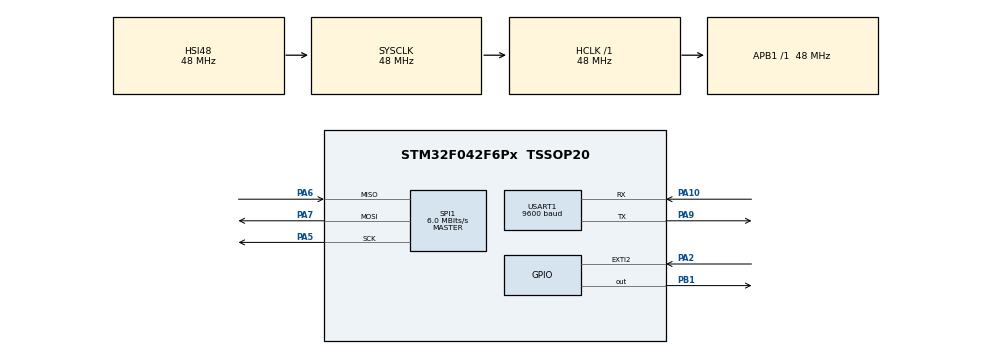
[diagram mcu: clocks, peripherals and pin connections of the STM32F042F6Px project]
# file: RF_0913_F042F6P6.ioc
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Dma.Request0=USART1_RX
Dma.Request1=USART1_TX
Dma.USART1_RX.0.Direction=DMA_PERIPH_TO_MEMORY
Dma.USART1_RX.0.Instance=DMA1_Channel3
Dma.USART1_RX.0.MemDataAlignment=DMA_MDATAALIGN_BYTE
Dma.USART1_RX.0.MemInc=DMA_MINC_ENABLE
Dma.USART1_RX.0.Mode=DMA_CIRCULAR
Dma.USART1_RX.0.PeriphDataAlignment=DMA_PDATAALIGN_BYTE
Dma.USART1_RX.0.PeriphInc=DMA_PINC_DISABLE
Dma.USART1_RX.0.Priority=DMA_PRIORITY_HIGH
Dma.USART1_TX.1.Direction=DMA_MEMORY_TO_PERIPH
Dma.USART1_TX.1.Instance=DMA1_Channel2
Dma.USART1_TX.1.MemDataAlignment=DMA_MDATAALIGN_BYTE
Dma.USART1_TX.1.MemInc=DMA_MINC_ENABLE
Dma.USART1_TX.1.Mode=DMA_NORMAL
Dma.USART1_TX.1.PeriphDataAlignment=DMA_PDATAALIGN_BYTE
Dma.USART1_TX.1.PeriphInc=DMA_PINC_DISABLE
Dma.USART1_TX.1.Priority=DMA_PRIORITY_HIGH
Mcu.Family=STM32F0
Mcu.Name=STM32F042F6Px
Mcu.Package=TSSOP20
NVIC.DMA1_Channel2_3_IRQn=true\:0\:0\:false\:false\:true
NVIC.EXTI2_3_IRQn=true\:0\:0\:false\:false\:true
NVIC.USART1_IRQn=true\:0\:0\:false\:false\:true
PA10.Mode=Asynchronous
PA10.Signal=USART1_RX
PA13.Mode=Serial_Wire
PA13.Signal=SYS_SWDIO
PA14.Mode=Serial_Wire
PA14.Signal=SYS_SWCLK
PA2.GPIO_ModeDefaultEXTI=GPIO_MODE_IT_FALLING
PA2.Signal=GPXTI2
PA5.GPIO_PuPd=GPIO_PULLDOWN
PA5.Mode=Full_Duplex_Master
PA5.Signal=SPI1_SCK
PA6.Mode=Full_Duplex_Master
PA6.Signal=SPI1_MISO
PA7.Mode=Full_Duplex_Master
PA7.Signal=SPI1_MOSI
PA9.Mode=Asynchronous
PA9.Signal=USART1_TX
PB1.PinState=GPIO_PIN_SET
PB1.Signal=GPIO_Output
ProjectManager.HeapSize=0x200
ProjectManager.StackSize=0x400
ProjectManager.TargetToolchain=MDK-ARM V5
RCC.AHBFreq_Value=48000000
RCC.APB1Freq_Value=48000000
RCC.APB1TimFreq_Value=48000000
RCC.HCLKFreq_Value=48000000
RCC.SYSCLKFreq_VALUE=48000000
RCC.SYSCLKSource=RCC_SYSCLKSOURCE_HSI48
SPI1.BaudRatePrescaler=SPI_BAUDRATEPRESCALER_8
SPI1.CalculateBaudRate=6.0 MBits/s
SPI1.DataSize=SPI_DATASIZE_8BIT
SPI1.Mode=SPI_MODE_MASTER
USART1.AutoBaudRateEnableParam=UART_ADVFEATURE_AUTOBAUDRATE_DISABLE
USART1.BaudRate=9600
USART1.WordLength=UART_WORDLENGTH_8B
VP_IWDG_VS_IWDG.Mode=IWDG_Activate
board=RF_0913_F042F6P6

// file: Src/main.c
/**
  ******************************************************************************
  * File Name          : main.c
  * Description        : Main program body
  ******************************************************************************
  *
  * COPYRIGHT(c) 2016 STMicroelectronics
  *
  * Redistribution and use in source and binary forms, with or without modification,
  * are permitted provided that the following conditions are met:
  *   1. Redistributions of source code must retain the above copyright notice,
  *      this list of conditions and the following disclaimer.
  *   2. Redistributions in binary form must reproduce the above copyright notice,
  *      this list of conditions and the following disclaimer in the documentation
  *      and/or other materials provided with the distribution.
  *   3. Neither the name of STMicroelectronics nor the names of its contributors
  *      may be used to endorse or promote products derived from this software
  *      without specific prior written permission.
  *
  * THIS SOFTWARE IS PROVIDED BY THE COPYRIGHT HOLDERS AND CONTRIBUTORS "AS IS"
  * AND ANY EXPRESS OR IMPLIED WARRANTIES, INCLUDING, BUT NOT LIMITED TO, THE
  * IMPLIED WARRANTIES OF MERCHANTABILITY AND FITNESS FOR A PARTICULAR PURPOSE ARE
  * DISCLAIMED. IN NO EVENT SHALL THE COPYRIGHT HOLDER OR CONTRIBUTORS BE LIABLE
  * FOR ANY DIRECT, INDIRECT, INCIDENTAL, SPECIAL, EXEMPLARY, OR CONSEQUENTIAL
  * DAMAGES (INCLUDING, BUT NOT LIMITED TO, PROCUREMENT OF SUBSTITUTE GOODS OR
  * SERVICES; LOSS OF USE, DATA, OR PROFITS; OR BUSINESS INTERRUPTION) HOWEVER
  * CAUSED AND ON ANY THEORY OF LIABILITY, WHETHER IN CONTRACT, STRICT LIABILITY,
  * OR TORT (INCLUDING NEGLIGENCE OR OTHERWISE) ARISING IN ANY WAY OUT OF THE USE
  * OF THIS SOFTWARE, EVEN IF ADVISED OF THE POSSIBILITY OF SUCH DAMAGE.
  *
  ******************************************************************************
  */
#include "stm32f0xx_hal.h"

/* USER CODE BEGIN Includes */
#include "stm32f0xx.h"
#include "main.h"
#include "flash.h"
#include "CC1121.h"
#include "CC1121_gpio.h"
#include "RF_parameter_setting.h"
#include "systick_timer.h"

/* USER CODE END Includes */

IWDG_HandleTypeDef hiwdg;

SPI_HandleTypeDef hspi1;

UART_HandleTypeDef huart1;
DMA_HandleTypeDef hdma_usart1_rx;
DMA_HandleTypeDef hdma_usart1_tx;

/* USER CODE BEGIN PV */
/* Private variables ---------------------------------------------------------*/
extern CC1121_RF_RX_DATA RF_RECEIVE_DATA;;
extern CC1121_RF_txDATA_DEF  Data_Packet_Tx;
#define u8 unsigned char
unsigned char uart_dma_state=1;

uint32_t uBrate=9600;
/* USER CODE END PV */

void SystemClock_Config(void);
void Error_Handler(void);
static void MX_GPIO_Init(void);
static void MX_DMA_Init(void);
static void MX_IWDG_Init(void);
static void MX_SPI1_Init(void);
static void MX_USART1_UART_Init(void);

/* USER CODE BEGIN PFP */
/* Private function prototypes -----------------------------------------------*/

/* USER CODE END PFP */

/* USER CODE BEGIN 0 */

void HW_RE_Configuration()
{
	Si4463_GpioInt();
	//HAL_DMA_Abort_IT(&hdma_usart1_tx);
	//HAL_DMA_Abort_IT(&hdma_usart1_rx);

	RF_parameters_init();
	RF_parameters_read();

	MX_USART1_UART_Init();
//	sdn_reset();// reset RF
	RF_CC1121_Init();  // RF INIT
//	delay_us(200);
//	spi_read_info();
//	delay_us(200);

	HAL_NVIC_EnableIRQ(EXTI2_3_IRQn);
	HAL_NVIC_ClearPendingIRQ(EXTI2_3_IRQn);
	HAL_NVIC_SetPriority(EXTI2_3_IRQn, 1, 0);
	delay_us(200);
	//rx_init();
	__HAL_UART_CLEAR_IDLEFLAG(&huart1);
	//HAL_IWDG_Start(&hiwdg);//start iwdg
}
void HW_init()
{
	Si4463_GpioInt();
	HAL_DMA_Abort_IT(&hdma_usart1_tx);
	HAL_DMA_Abort_IT(&hdma_usart1_rx);

	RF_parameters_init();
	RF_parameters_read();

	MX_USART1_UART_Init();
	HAL_UART_Receive_DMA(&huart1,Data_Packet_Tx.rf_tx_data_buff,buffer_size);
	__HAL_UART_ENABLE_IT(&huart1, UART_IT_IDLE);    //??????
//  Sample_Timer_Init();
//	sdn_reset();// reset RF
	  //PROC_MANUFACTURE_Do();              //灵敏度测试程序，GPIO0为信号输出433M 9.6K 15K

	  RF_CC1121_Init();  // RF INIT

//	delay_us(200);
//	spi_read_info();
//	delay_us(200);

	HAL_NVIC_EnableIRQ(EXTI2_3_IRQn);
	HAL_NVIC_ClearPendingIRQ(EXTI2_3_IRQn);
	HAL_NVIC_SetPriority(EXTI2_3_IRQn, 1, 0);

	delay_us(200);
	RF_RECEIVE_DATA.rf_receive_end_flag=0;
//	rx_init();
	__HAL_UART_CLEAR_IDLEFLAG(&huart1);

	//HAL_IWDG_Start(&hiwdg);//start iwdg
}

/* USER CODE END 0 */

int main(void)
{

	/* MCU Configuration----------------------------------------------------------*/

	/* Reset of all peripherals, Initializes the Flash interface and the Systick. */
	HAL_Init();

	/* Configure the system clock */
	SystemClock_Config();

	/* Initialize all configured peripherals */
	MX_GPIO_Init();
	MX_DMA_Init();
	MX_IWDG_Init();
	MX_SPI1_Init();
// MX_USART1_UART_Init();

	/* USER CODE BEGIN 2 */
//GetLockCode();
//rev_ID_write(Lock_Code1);
//Lock_Code=0;
//Lock_Code=rev_ID_read();
//	if(Lock_Code != Lock_Code1)
	//	return 0; //??0x123456789ABC??????ID
	HW_init();
	//Sample_Timer_Init();
// IO_TEST();
	/* USER CODE END 2 */

	/* Infinite loop */
	while (1)
	{

		/* USER CODE BEGIN 3 */
		//RF_TX_RX_CTRL();
		RF_Process();
		// HAL_IWDG_Refresh(&hiwdg);//watch dog

	}
	/* USER CODE END 3 */

}

/** System Clock Configuration
*/
void SystemClock_Config(void)
{

	RCC_OscInitTypeDef RCC_OscInitStruct;
	RCC_ClkInitTypeDef RCC_ClkInitStruct;
	RCC_PeriphCLKInitTypeDef PeriphClkInit;

	RCC_OscInitStruct.OscillatorType = RCC_OSCILLATORTYPE_HSI48|RCC_OSCILLATORTYPE_LSI;
	RCC_OscInitStruct.HSI48State = RCC_HSI48_ON;
	RCC_OscInitStruct.LSIState = RCC_LSI_ON;
	RCC_OscInitStruct.PLL.PLLState = RCC_PLL_NONE;
	if (HAL_RCC_OscConfig(&RCC_OscInitStruct) != HAL_OK)
	{
		Error_Handler();
	}

	RCC_ClkInitStruct.ClockType = RCC_CLOCKTYPE_HCLK|RCC_CLOCKTYPE_SYSCLK
	                              |RCC_CLOCKTYPE_PCLK1;
	RCC_ClkInitStruct.SYSCLKSource = RCC_SYSCLKSOURCE_HSI48;
	RCC_ClkInitStruct.AHBCLKDivider = RCC_SYSCLK_DIV1;
	RCC_ClkInitStruct.APB1CLKDivider = RCC_HCLK_DIV1;
	if (HAL_RCC_ClockConfig(&RCC_ClkInitStruct, FLASH_LATENCY_1) != HAL_OK)
	{
		Error_Handler();
	}

	PeriphClkInit.PeriphClockSelection = RCC_PERIPHCLK_USART1;
	PeriphClkInit.Usart1ClockSelection = RCC_USART1CLKSOURCE_PCLK1;
	if (HAL_RCCEx_PeriphCLKConfig(&PeriphClkInit) != HAL_OK)
	{
		Error_Handler();
	}

	HAL_SYSTICK_Config(HAL_RCC_GetHCLKFreq()/1000);

	HAL_SYSTICK_CLKSourceConfig(SYSTICK_CLKSOURCE_HCLK);

	/* SysTick_IRQn interrupt configuration */
	HAL_NVIC_SetPriority(SysTick_IRQn, 0, 0);
}

/* IWDG init function */
static void MX_IWDG_Init(void)
{

	hiwdg.Instance = IWDG;
	hiwdg.Init.Prescaler = IWDG_PRESCALER_4;
	hiwdg.Init.Window = 4095;
	hiwdg.Init.Reload = 4095;
	if (HAL_IWDG_Init(&hiwdg) != HAL_OK)
	{
		Error_Handler();
	}

}

/* SPI1 init function */
static void MX_SPI1_Init(void)
{

	hspi1.Instance = SPI1;
	hspi1.Init.Mode = SPI_MODE_MASTER;
	hspi1.Init.Direction = SPI_DIRECTION_2LINES;
	hspi1.Init.DataSize = SPI_DATASIZE_8BIT;
	hspi1.Init.CLKPolarity = SPI_POLARITY_LOW;
	hspi1.Init.CLKPhase = SPI_PHASE_1EDGE;
	hspi1.Init.NSS = SPI_NSS_SOFT;
	hspi1.Init.BaudRatePrescaler = SPI_BAUDRATEPRESCALER_8;
	hspi1.Init.FirstBit = SPI_FIRSTBIT_MSB;
	hspi1.Init.TIMode = SPI_TIMODE_DISABLE;
	hspi1.Init.CRCCalculation = SPI_CRCCALCULATION_DISABLE;
	hspi1.Init.CRCPolynomial = 7;
	hspi1.Init.CRCLength = SPI_CRC_LENGTH_DATASIZE;
	hspi1.Init.NSSPMode = SPI_NSS_PULSE_ENABLE;
	if (HAL_SPI_Init(&hspi1) != HAL_OK)
	{
		Error_Handler();
	}

}

/* USART1 init function */
static void MX_USART1_UART_Init(void)
{

	huart1.Instance = USART1;
	huart1.Init.BaudRate = uBrate;
	huart1.Init.WordLength = UART_WORDLENGTH_8B;
	huart1.Init.StopBits = UART_STOPBITS_1;
	huart1.Init.Parity = UART_PARITY_NONE;
	huart1.Init.Mode = UART_MODE_TX_RX;
	huart1.Init.HwFlowCtl = UART_HWCONTROL_NONE;
	huart1.Init.OverSampling = UART_OVERSAMPLING_16;
	huart1.Init.OneBitSampling = UART_ONE_BIT_SAMPLE_DISABLE;
	huart1.AdvancedInit.AdvFeatureInit = UART_ADVFEATURE_NO_INIT;
	if (HAL_UART_Init(&huart1) != HAL_OK)
	{
		Error_Handler();
	}

}

static void MX_DMA_Init(void)
{
	/* DMA controller clock enable */
	__HAL_RCC_DMA1_CLK_ENABLE();

	/* DMA interrupt init */
	/* DMA1_Channel2_3_IRQn interrupt configuration */
	HAL_NVIC_SetPriority(DMA1_Channel2_3_IRQn, 0, 0);
	HAL_NVIC_EnableIRQ(DMA1_Channel2_3_IRQn);

}

/** Configure pins as
        * Analog
        * Input
        * Output
        * EVENT_OUT
        * EXTI
*/
static void MX_GPIO_Init(void)
{

	GPIO_InitTypeDef GPIO_InitStruct;

	/* GPIO Ports Clock Enable */
	__HAL_RCC_GPIOA_CLK_ENABLE();
	__HAL_RCC_GPIOB_CLK_ENABLE();

	/*Configure GPIO pin : PA3 */
	GPIO_InitStruct.Pin = GPIO_PIN_3;
	GPIO_InitStruct.Mode = GPIO_MODE_IT_FALLING;
	GPIO_InitStruct.Pull = GPIO_NOPULL;
	HAL_GPIO_Init(GPIOA, &GPIO_InitStruct);

	/*Configure GPIO pin : PB1 */
	GPIO_InitStruct.Pin = GPIO_PIN_2;
	GPIO_InitStruct.Mode = GPIO_MODE_OUTPUT_PP;
	GPIO_InitStruct.Pull = GPIO_NOPULL;
	GPIO_InitStruct.Speed = GPIO_SPEED_FREQ_LOW;
	HAL_GPIO_Init(GPIOA, &GPIO_InitStruct);

	/*Configure GPIO pin Output Level */
	HAL_GPIO_WritePin(GPIOA, GPIO_PIN_1, GPIO_PIN_SET);

	/* EXTI interrupt init*/
	HAL_NVIC_SetPriority(EXTI2_3_IRQn, 0, 0);
	HAL_NVIC_EnableIRQ(EXTI2_3_IRQn);

}

/* USER CODE BEGIN 4 */

void HAL_GPIO_EXTI_Callback(uint16_t GPIO_Pin)
{
	if(GPIO_Pin==GPIO_PIN_3)
	{
		RF_RECEIVE_DATA.rf_receive_end_flag=1;

	}
}

void HAL_UART_TxCpltCallback(UART_HandleTypeDef *huart)
{
	uart_dma_state=1;

}
/* USER CODE END 4 */

void Error_Handler(void)
{
	while(1)
	{
	}
}

/************************ (C) COPYRIGHT STMicroelectronics *****END OF FILE****/
